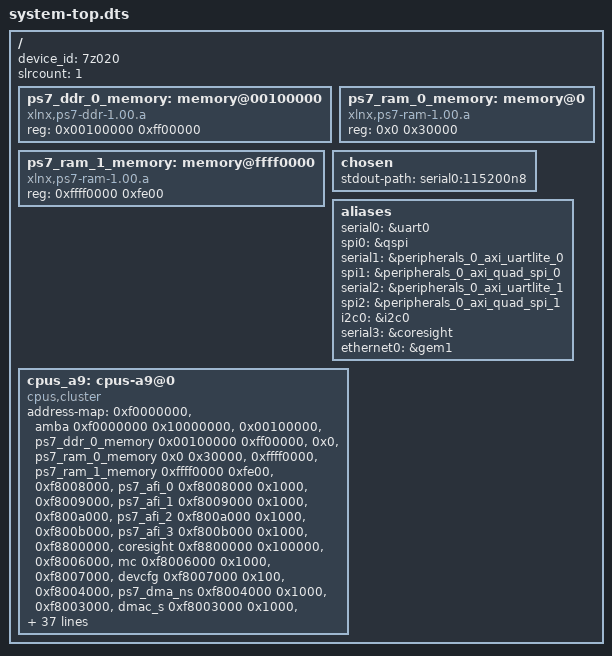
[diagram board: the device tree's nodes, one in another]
/dts-v1/;
#include "zynq-7000.dtsi"
#include "pl.dtsi"
#include "pcw.dtsi"
/ {
	device_id = "7z020";
	slrcount = <1>;
	ps7_ddr_0_memory: memory@00100000 {
		compatible = "xlnx,ps7-ddr-1.00.a";
		device_type = "memory";
		reg = <0x00100000 0xff00000>;
	};
	ps7_ram_0_memory: memory@0 {
		compatible = "xlnx,ps7-ram-1.00.a";
		device_type = "memory";
		reg = <0x0 0x30000>;
	};
	ps7_ram_1_memory: memory@ffff0000 {
		compatible = "xlnx,ps7-ram-1.00.a";
		device_type = "memory";
		reg = <0xffff0000 0xfe00>;
	};
	chosen {
		stdout-path = "serial0:115200n8";
	};
	aliases {
		serial0 = &uart0;
		spi0 = &qspi;
		serial1 = &peripherals_0_axi_uartlite_0;
		spi1 = &peripherals_0_axi_quad_spi_0;
		serial2 = &peripherals_0_axi_uartlite_1;
		spi2 = &peripherals_0_axi_quad_spi_1;
		i2c0 = &i2c0;
		serial3 = &coresight;
		ethernet0 = &gem1;
	};
	cpus_a9: cpus-a9@0 {
		compatible = "cpus,cluster";
		address-map = <0xf0000000 &amba 0xf0000000 0x10000000>, 
			      <0x00100000 &ps7_ddr_0_memory 0x00100000 0xff00000>, 
			      <0x0 &ps7_ram_0_memory 0x0 0x30000>, 
			      <0xffff0000 &ps7_ram_1_memory 0xffff0000 0xfe00>, 
			      <0xf8008000 &ps7_afi_0 0xf8008000 0x1000>, 
			      <0xf8009000 &ps7_afi_1 0xf8009000 0x1000>, 
			      <0xf800a000 &ps7_afi_2 0xf800a000 0x1000>, 
			      <0xf800b000 &ps7_afi_3 0xf800b000 0x1000>, 
			      <0xf8800000 &coresight 0xf8800000 0x100000>, 
			      <0xf8006000 &mc 0xf8006000 0x1000>, 
			      <0xf8007000 &devcfg 0xf8007000 0x100>, 
			      <0xf8004000 &ps7_dma_ns 0xf8004000 0x1000>, 
			      <0xf8003000 &dmac_s 0xf8003000 0x1000>, 
			      <0xe000c000 &gem1 0xe000c000 0x1000>, 
			      <0xf8f00200 &global_timer 0xf8f00200 0x100>, 
			      <0xf8900000 &ps7_gpv_0 0xf8900000 0x100000>, 
			      <0xe0004000 &i2c0 0xe0004000 0x1000>, 
			      <0xf8f01000 &intc 0xf8f01000 0x1000>, 
			      <0xe0200000 &ps7_iop_bus_config_0 0xe0200000 0x1000>, 
			      <0xf8f02000 &L2 0xf8f02000 0x1000>, 
			      <0xf800c000 &ps7_ocmc_0 0xf800c000 0x1000>, 
			      <0xf8891000 &ps7_pmu_0 0xf8891000 0x1000>, 
			      <0xe000d000 &qspi 0xe000d000 0x1000>, 
			      <0xfc000000 &ps7_qspi_linear_0 0xfc000000 0x1000000>, 
			      <0xf8f00000 &ps7_scuc_0 0xf8f00000 0xfd>, 
			      <0xf8f00600 &scutimer 0xf8f00600 0x20>, 
			      <0xf8f00620 &scuwdt 0xf8f00620 0xe0>, 
			      <0xe0101000 &sdhci1 0xe0101000 0x1000>, 
			      <0xf8000000 &slcr 0xf8000000 0x1000>, 
			      <0xf8001000 &ttc0 0xf8001000 0x1000>, 
			      <0xe0000000 &uart0 0xe0000000 0x1000>, 
			      <0xe0003000 &usb1 0xe0003000 0x1000>, 
			      <0xf8007100 &adc 0xf8007100 0x21>, 
			      <0x41200000 &peripherals_0_axi_gpio_0 0x41200000 0x10000>, 
			      <0x41210000 &sensor_0_axi_gpio_0 0x41210000 0x10000>, 
			      <0x41e00000 &peripherals_0_axi_quad_spi_0 0x41e00000 0x10000>, 
			      <0x41e10000 &peripherals_0_axi_quad_spi_1 0x41e10000 0x10000>, 
			      <0x42c00000 &peripherals_0_axi_uartlite_0 0x42c00000 0x10000>, 
			      <0x42c10000 &peripherals_0_axi_uartlite_1 0x42c10000 0x10000>, 
			      <0x43000000 &evf_0_axi_vdma_0 0x43000000 0x10000>, 
			      <0x43c00000 &evf_0_mipi_dsi_tx_subsystem_0 0x43c00000 0x10000>;
		#ranges-address-cells = <0x1>;
		#ranges-size-cells = <0x1>;
	};
};
